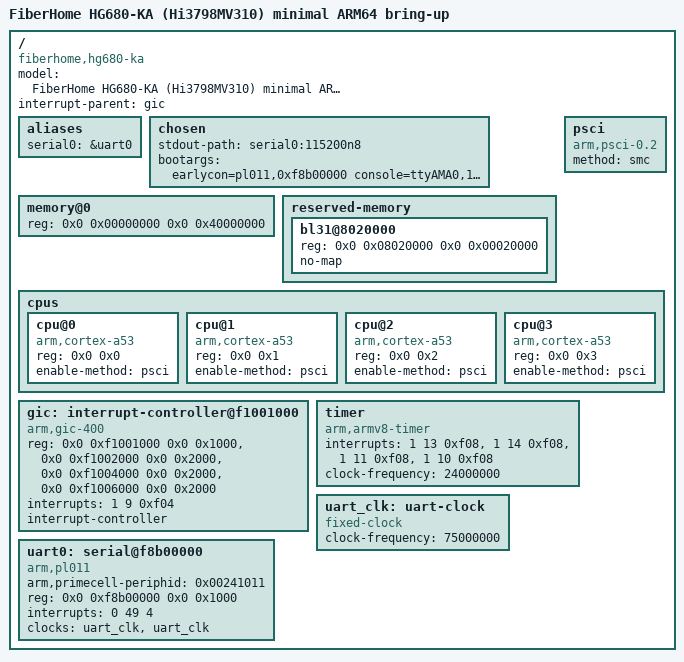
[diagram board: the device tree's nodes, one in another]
/dts-v1/;

/ {
	model = "FiberHome HG680-KA (Hi3798MV310) minimal ARM64 bring-up";
	compatible = "fiberhome,hg680-ka", "hisilicon,hi3798mv310";

	#address-cells = <2>;
	#size-cells = <2>;
	interrupt-parent = <&gic>;

	aliases {
		serial0 = &uart0;
	};

	chosen {
		stdout-path = "serial0:115200n8";
		bootargs = "earlycon=pl011,0xf8b00000 console=ttyAMA0,115200n8 keep_bootcon ignore_loglevel loglevel=8 panic=-1";
	};

	memory@0 {
		device_type = "memory";
		reg = <0x0 0x00000000 0x0 0x40000000>;
	};

	/*
	 * BL31 remains resident here after the factory Fastboot -> TF-A handoff.
	 * Linux must never allocate or map this RAM as ordinary memory because
	 * PSCI/SMC continues executing from it after the kernel starts.
	 */
	reserved-memory {
		#address-cells = <2>;
		#size-cells = <2>;
		ranges;

		bl31@8020000 {
			reg = <0x0 0x08020000 0x0 0x00020000>;
			no-map;
		};
	};

	psci {
		compatible = "arm,psci-0.2";
		method = "smc";
	};

	cpus {
		#address-cells = <2>;
		#size-cells = <0>;

		cpu@0 {
			device_type = "cpu";
			compatible = "arm,cortex-a53";
			reg = <0x0 0x0>;
			enable-method = "psci";
		};

		cpu@1 {
			device_type = "cpu";
			compatible = "arm,cortex-a53";
			reg = <0x0 0x1>;
			enable-method = "psci";
		};

		cpu@2 {
			device_type = "cpu";
			compatible = "arm,cortex-a53";
			reg = <0x0 0x2>;
			enable-method = "psci";
		};

		cpu@3 {
			device_type = "cpu";
			compatible = "arm,cortex-a53";
			reg = <0x0 0x3>;
			enable-method = "psci";
		};
	};

	/* Hi3798MV310 exposes the same GICv2 base layout as the related CV200. */
	gic: interrupt-controller@f1001000 {
		compatible = "arm,gic-400";
		reg = <0x0 0xf1001000 0x0 0x1000>,
		      <0x0 0xf1002000 0x0 0x2000>,
		      <0x0 0xf1004000 0x0 0x2000>,
		      <0x0 0xf1006000 0x0 0x2000>;
		interrupts = <1 9 0xf04>;
		#address-cells = <0>;
		#interrupt-cells = <3>;
		interrupt-controller;
	};

	/*
	 * ARM architected timer PPI order: secure physical, non-secure physical,
	 * virtual, hypervisor. 24 MHz matches the MV310 boot/TF-A counter setup.
	 */
	timer {
		compatible = "arm,armv8-timer";
		interrupts = <1 13 0xf08>,
			     <1 14 0xf08>,
			     <1 11 0xf08>,
			     <1 10 0xf08>;
		clock-frequency = <24000000>;
	};

	uart_clk: uart-clock {
		compatible = "fixed-clock";
		#clock-cells = <0>;
		clock-frequency = <75000000>;
	};

	uart0: serial@f8b00000 {
		compatible = "arm,pl011", "arm,primecell";
		arm,primecell-periphid = <0x00241011>;
		reg = <0x0 0xf8b00000 0x0 0x1000>;
		interrupts = <0 49 4>;
		clocks = <&uart_clk>, <&uart_clk>;
		clock-names = "uartclk", "apb_pclk";
		status = "okay";
	};
};
